# N32H7xx register map
Vendor: Nationstech Ltd.; File version: 1.0
CPU: CM7 r1p1, little endian, MPU, FPU, 4 interrupt priority bits
Registers are 32-bit, read-write, reset 0x0 unless marked. A register's access mark holds for its fields unless they carry their own. Offsets are from the block's base; [hi:lo] are bit positions; {n}, {i} and the like mark numbered series.

## ADC1 — Analog to digital converter
Base 0x40044000
Same registers: ADC2 0x40044400, ADC3 0x40044800
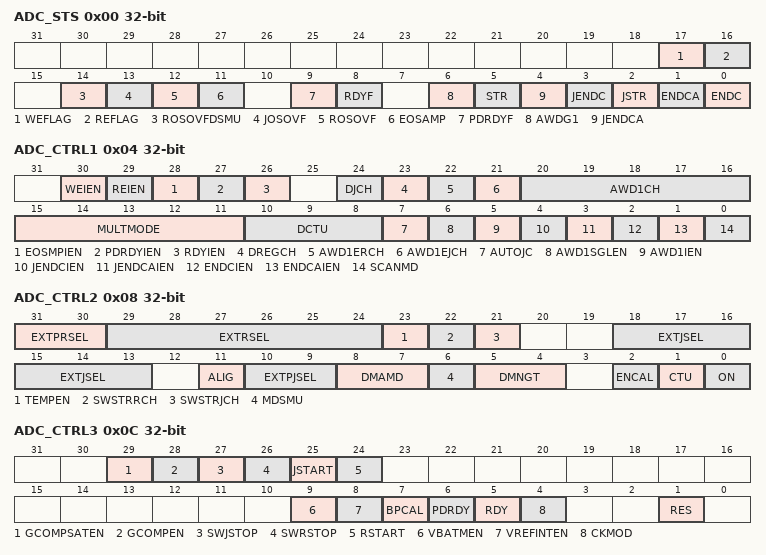
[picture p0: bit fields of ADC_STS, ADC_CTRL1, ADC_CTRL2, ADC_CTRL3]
0x00 ADC_STS — ADC status register
  [17] WEFLAG, [16] REFLAG, [14] ROSOVFDSMU, [13] JOSOVF, [12] ROSOVF, [11] EOSAMP, [9] PDRDYF, [8] RDYF, [6] AWDG1, [5] STR, [4] JENDCA, [3] JENDC, [2] JSTR, [1] ENDCA, [0] ENDC
0x04 ADC_CTRL1 — ADC control register 1
  [30] WEIEN, [29] REIEN, [28] EOSMPIEN, [27] PDRDYIEN, [26] RDYIEN, [24] DJCH, [23] DREGCH, [22] AWD1ERCH, [21] AWD1EJCH, [20:16] AWD1CH, [15:11] MULTMODE, [10:8] DCTU, [7] AUTOJC, [6] AWD1SGLEN, [5] AWD1IEN, [4] JENDCIEN, [3] JENDCAIEN, [2] ENDCIEN, [1] ENDCAIEN, [0] SCANMD
0x08 ADC_CTRL2 — ADC control register 2
  [31:30] EXTPRSEL, [29:24] EXTRSEL, [23] TEMPEN, [22] SWSTRRCH, [21] SWSTRJCH, [18:13] EXTJSEL, [11] ALIG, [10:9] EXTPJSEL, [8:7] DMAMD, [6] MDSMU, [5:4] DMNGT, [2] ENCAL, [1] CTU, [0] ON
0x0C ADC_CTRL3 — ADC control register 3
  [29] GCOMPSATEN, [28] GCOMPEN, [27] SWJSTOP, [26] SWRSTOP, [25] JSTART, [24] RSTART, [9] VBATMEN, [8] VREFINTEN, [7] BPCAL, [6] PDRDY, [5] RDY, [4] CKMOD, [1] RES
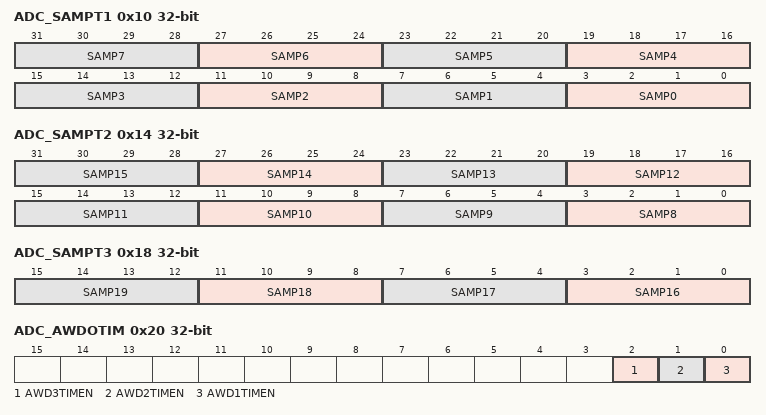
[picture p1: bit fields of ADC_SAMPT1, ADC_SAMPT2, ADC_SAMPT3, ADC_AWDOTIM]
0x10 ADC_SAMPT1 — Sample time register 2
  [4n+3:4n] SAMP{n} (n=0..7)
0x14 ADC_SAMPT2 — sample time register 2
  [4n-29:4n-32] SAMP{n} (n=8..15)
0x18 ADC_SAMPT3 — sample time register 3
  [4n-61:4n-64] SAMP{n} (n=16..19)
0x1C ADC_DIFSEL — ADC Differential Mode Selection Register
  [19:1] DIFSEL
0x20 ADC_AWDOTIM — ADC analog watch dog for timer
  [2] AWD3TIMEN, [1] AWD2TIMEN, [0] AWD1TIMEN
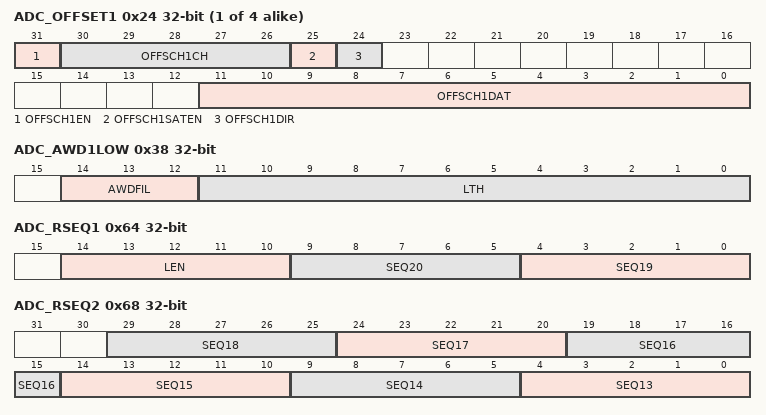
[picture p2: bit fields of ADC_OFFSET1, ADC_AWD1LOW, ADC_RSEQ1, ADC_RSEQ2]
{0x20+4i} ADC_OFFSET{i} (i=1..4) — ADC offset register {i}
  [31] OFFSCH{i}EN, [30:26] OFFSCH{i}CH, [25] OFFSCH{i}SATEN, [24] OFFSCH{i}DIR, [11:0] OFFSCH{i}DAT
{0x2C+8i} ADC_AWD{i}HIGH reset 0xFFF (i=1..3) — ADC watchdog {i} high threshold register
  [11:0] HTH
0x38 ADC_AWD1LOW — ADC watchdog low threshold register
  [14:12] AWDFIL, [11:0] LTH
0x40 ADC_AWD2LOW — ADC watchdog 2 low threshold register
  [11:0] LTH
0x48 ADC_AWD3LOW — ADC watchdog 3 low threshold register
  [11:0] LTH
0x4C ADC_AWD2EN — ADC watchdog threshold flag
  [19:0] AWD2EN
0x50 ADC_AWD3EN — ADC watchdog threshold flag
  [19:0] AWD3EN
0x54 ADC_AWD2INTEN — ADC watchdog threshold flag
  [19:0] AWD2INTEN
0x58 ADC_AWD3INTEN — ADC watchdog threshold flag
  [19:0] AWD3INTEN
0x5C ADC_AWD2STS — ADC watchdog threshold flag
  [19:0] AWD2FLAG
0x60 ADC_AWD3STS — ADC watchdog threshold flag
  [19:0] AWD3FLAG
0x64 ADC_RSEQ1 — ADC regular sequence register 1
  [14:10] LEN, [9:5] SEQ20, [4:0] SEQ19
0x68 ADC_RSEQ2 — ADC regular sequence register 2
  [5n-61:5n-65] SEQ{n} (n=13..18)
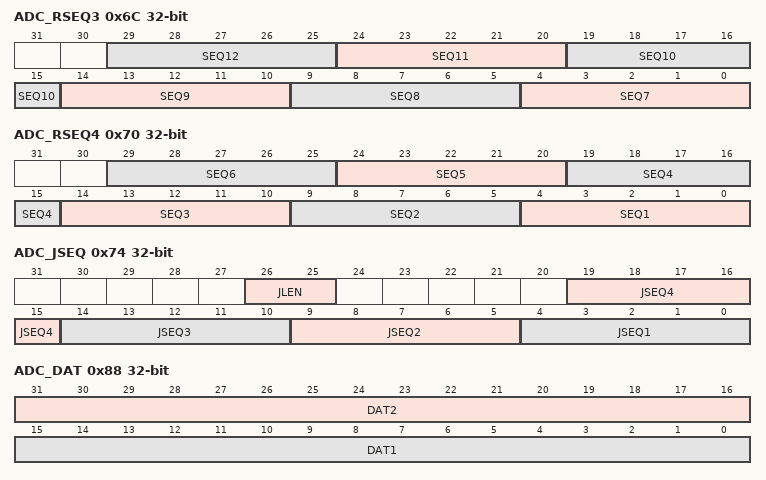
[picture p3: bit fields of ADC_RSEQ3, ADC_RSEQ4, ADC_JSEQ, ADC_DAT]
0x6C ADC_RSEQ3 — ADC regular sequence register 3
  [5n-31:5n-35] SEQ{n} (n=7..12)
0x70 ADC_RSEQ4 — ADC regular sequence register 4
  [5n-1:5n-5] SEQ{n} (n=1..6)
0x74 ADC_JSEQ — ADC injected sequence register
  [26:25] JLEN, [5n-1:5n-5] JSEQ{n} (n=1..4)
{0x74+4i} ADC_JDAT{i} ro (i=1..4) — ADC injected data register x
  [15:0] JDAT
0x88 ADC_DAT ro — ADC regular data register
  [31:16] DAT2, [15:0] DAT1
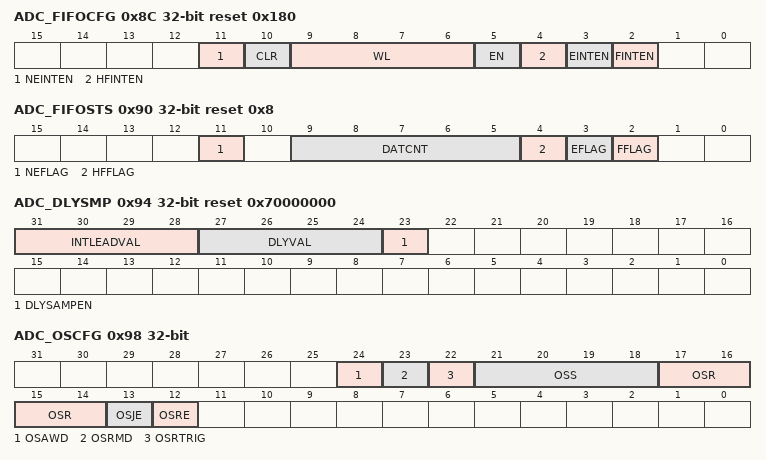
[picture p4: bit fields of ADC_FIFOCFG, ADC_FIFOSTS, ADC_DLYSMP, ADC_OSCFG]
0x8C ADC_FIFOCFG reset 0x180 — ADC fifo config register
  [11] NEINTEN, [10] CLR, [9:6] WL, [5] EN, [4] HFINTEN, [3] EINTEN, [2] FINTEN
0x90 ADC_FIFOSTS reset 0x8 — ADC fifo status register
  [11] NEFLAG, [9:5] DATCNT ro, [4] HFFLAG, [3] EFLAG, [2] FFLAG
0x94 ADC_DLYSMP reset 0x70000000 — ADC delay config register
  [31:28] INTLEADVAL, [27:24] DLYVAL, [23] DLYSAMPEN
0x98 ADC_OSCFG — ADC oversample register
  [24] OSAWD, [23] OSRMD, [22] OSRTRIG, [21:18] OSS, [17:14] OSR, [13] OSJE, [12] OSRE
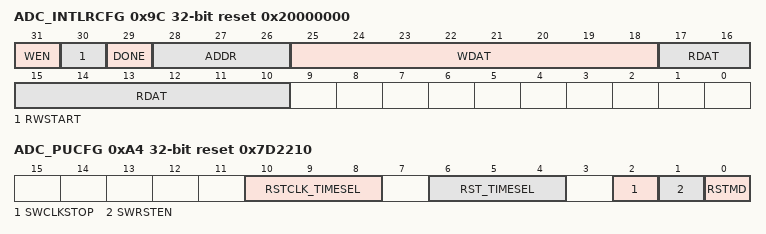
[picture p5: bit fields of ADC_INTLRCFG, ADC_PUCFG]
0x9C ADC_INTLRCFG reset 0x20000000 — ADC Internal Register Configuration Register
  [31] WEN
  [30] RWSTART wo — START
  [29] DONE ro
  [28:26] ADDR
  [25:18] WDAT
  [17:10] RDAT ro
0xA0 ADC_GCOMP — ADC Gain compensation Register
  [13:0] GCOMPDAT
0xA4 ADC_PUCFG reset 0x7D2210 — ADC Power up configuration Register
  [10:8] RSTCLK_TIMESEL — RST_TIMESEL
  [6:4] RST_TIMESEL
  [2] SWCLKSTOP
  [1] SWRSTEN
  [0] RSTMD
